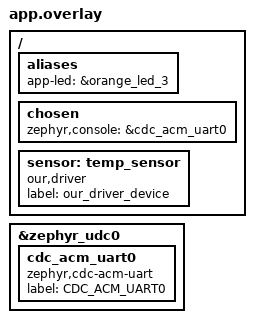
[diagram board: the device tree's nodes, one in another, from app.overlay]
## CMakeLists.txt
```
cmake_minimum_required(VERSION 3.20.0)


list(APPEND BOARD_ROOT ${CMAKE_CURRENT_SOURCE_DIR})
find_package(Zephyr REQUIRED)
project(iomico_zephyr_app)

target_sources(app PRIVATE src/main.cpp)

add_subdirectory(drivers/our_driver)
```

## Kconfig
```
menuconfig LED_SUBSYSTEM
  bool "Led Subsystem"
  default y

  if LED_SUBSYSTEM
    menu "LED blink sleep time (1s (medium))"  
      menuconfig ADVANCE_LED_SETTING
        bool "Advance LED setting"
        if ADVANCE_LED_SETTING  
          config LED_BRIGHTNESS
              int "LED brightmess (0-100)"
              default 10
              range 0 100
              help
                This is LED Brightness
          
          config LED_FADE_DURATION
              int "LED fade duration (ms)"
              default 50
              range 0 100
              help
                This is LED Fade
              
          menu "Expert settings"
            
            config ENABLE_LED_DEBUGGING
              bool "Enable LED debugging"
              default n
            config CUSTOME_BLINK
              bool "Custome blink pattern"
              default n

          endmenu
        endif
    endmenu
  endif



config APP_HEARTBEAT_PERIOD_MS
  int "LED heartbeat period (ms)"
  default 500
  range 100 2000
  help
    For Task 1 of Lecture 4

source "Kconfig.zephyr"
# rsource "boards\\copy_board\\Kconfig.copy_board"
rsource "drivers\\our_driver\\Kconfig"
```

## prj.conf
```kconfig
CONFIG_GPIO=y
CONFIG_LOG=y
CONFIG_SENSOR=y
CONFIG_CONSOLE=y

#for usb_cdc_acm as consol backend interface 
CONFIG_USB_CDC_ACM=y
CONFIG_USB_DEVICE_STACK=y
CONFIG_USB_DEVICE_VID=0x2fe3
CONFIG_USB_DEVICE_PID=0x0001
CONFIG_USB_DEVICE_INITIALIZE_AT_BOOT=y
CONFIG_SERIAL=y
CONFIG_UART_CONSOLE=y

#for shell
CONFIG_SHELL=y
```

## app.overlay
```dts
/{
    aliases{
        app-led = &orange_led_3;
    };

    chosen{
            zephyr,console =  &cdc_acm_uart0;
    };
    /*
    Modifying the chosen node zephyr,console to USB instead of UART2
    */
    sensor: temp_sensor{
        compatible = "our,driver";
        // calibration = <8>;
        status = "okay";
        label ="our_driver_device";
    };
};

/*
    so the hardware driver/peripheral for  USB device has a chilsd driver cdc_acm_uart0
    which is compatible with zephyr,cdc-acm-uart0
    --------------------------------------------
    USB OTG FS refers to the physical hardware peripheral on the STM32F4 (the controller),
    while USB CDC ACM refers to the communication protocol (the software device class)
    running through that hardware.

     1. USB OTG FS (Hardware / Peripheral)OTG: Stands for On-The-Go.
     It means the port can act as either a Device (like a mouse) or a Host (like a computer reading a flash drive).
     FS: Stands for Full Speed, meaning it runs at 12 Mbps.
     Role on STM32F4 Discovery: The STM32F4 Discovery board has a micro-AB USB port connected to this specific OTG FS peripheral,
     and can be used in Device or Host mode depending on your firmware.

     2. USB CDC ACM (Software / Communication Class)
     CDC: Stands for Communication Device Class.
     ACM: Stands for Abstract Control Model.
     Role on STM32F4 Discovery: This is the USB protocol that makes the microcontroller emulate a traditional
     RS-232 Virtual COM Port (VCP) when connected to a PC. Your computer sees it as a serial port (e.g., COM3 or /dev/ttyACM0)
     without needing custom drivers
*/
&zephyr_udc0 {
    cdc_acm_uart0: cdc_acm_uart0 {
        compatible = "zephyr,cdc-acm-uart";
        label = "CDC_ACM_UART0";
    };
};
```

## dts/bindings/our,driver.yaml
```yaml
description: Our custom sensor driver binding
compatible: "our,driver"
include: i2c-device.yaml

properties:
  callibration:
    type: int
    required: true
    
```

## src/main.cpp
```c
#include "sensor_custom.h"
#include <zephyr/drivers/gpio.h>
#include <zephyr/kernel.h>
#include <zephyr/logging/log.h>
#include <zephyr/device.h>

#define SLEEP_TIME_MS CONFIG_APP_HEARTBEAT_PERIOD_MS

/* The devicetree node identifier for the "led0" alias. */
#define LED_NODE DT_ALIAS(app_led)

static const struct gpio_dt_spec led = GPIO_DT_SPEC_GET(LED_NODE, gpios);

LOG_MODULE_REGISTER(main, LOG_LEVEL_INF);

int main(void)
{
    bool led_state = true;
    
    const struct device *dev = DEVICE_DT_GET_ANY(our_driver);

    if (!device_is_ready(dev)) {
        return -ENODEV;
    }

    /* Safely invoke your custom API to modify instance state variables */
    int ret = custom_data_set(dev, 42);
    
    LOG_INF("Data value chnaged successfully");

    if (!gpio_is_ready_dt(&led)) return 0;

    if (gpio_pin_configure_dt(&led, GPIO_OUTPUT_ACTIVE) < 0) return 0;

    while (1) {
        if (gpio_pin_toggle_dt(&led) < 0) return 0;

        led_state = !led_state;
        LOG_INF("LED state: %s", led_state ? "ON" : "OFF");
        k_msleep(SLEEP_TIME_MS);
    }
    return 0;
}
```

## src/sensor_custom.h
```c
#ifndef SENSOR_CUSTOM_H_
#define SENSOR_CUSTOM_H_

#include <stdint.h>
#include <zephyr/device.h>
#include <zephyr/drivers/sensor.h>

/*
To add a custom extension API to a Zephyr driver that already implements a standard subsystem,
you must define a custom API structure alongside your subsystem implementations, 
expose it via a public header file, and implement a wrapper function that extracts the device's internal data structure to mutate it
*/

/*
According to the official Zephyr Driver Model Documentation, drivers can support driver-specific extensions directly. 

Because your custom API is tied to your driver implementation and not part of the standard subsystem structure, 
you will bypass the standard const void *api pointer in struct device and invoke your custom driver functions directly by passing the device pointer.
OR
Because the driver is already bound to a standard subsystem (like sensor, GPIO, or I2C),
your extension bypasses the standard dev->api struct pointer and directly executes your custom implementation 
function while mutating your driver's runtime data pointer.
*/




typedef int (*custom_data_set_t) (const struct device *dev, int val);

struct sensor_custom_driver_api{
  custom_data_set_t data_set;

};

__syscall int custom_data_set(const struct device *dev,
			      int val);

// Define the public inline function called from main.c
static inline int custom_data_set(const struct device *dev, int val)
{
  /*Bypasssing the standard subsystem api structure reference*/
  // const struct sensor_custom_driver_api *api =
  //     (const struct sensor_custom_driver_api *)dev->api;

  extern const struct sensor_custom_driver_api custom_api_function;
  
  if (custom_api_function.data_set == NULL) {
    return -ENOSYS;
  }
  return custom_api_function.data_set(dev, val);
}



/* 
OPTION - 2
For implementing as a custom function 
*/

// int custom_data_set(const struct device *dev,
// 			      int val);

// #include <zephyr/syscalls/sensor_custom.h>

#endif
```

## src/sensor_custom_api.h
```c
#ifndef  SENSOR_CUSTOM_API_H
#define  SENSOR_CUSTOM_API_H

#include <zephyr/device.h>
#include <stdlib.h>


static int custom_api_devicedate (const struct device *dev, uint32_t val);

#endif
```
